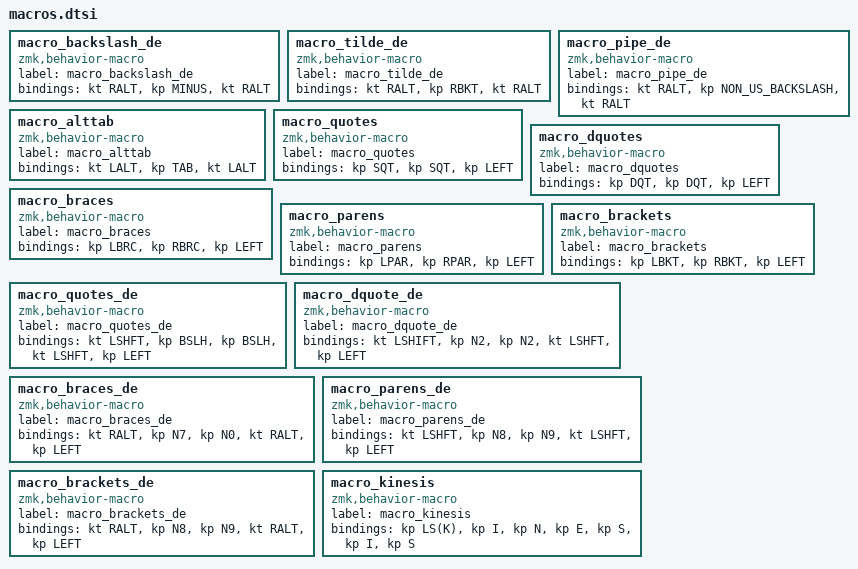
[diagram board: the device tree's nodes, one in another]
macro_backslash_de: macro_backslash_de{
compatible = "zmk,behavior-macro";
label = "macro_backslash_de";
#binding-cells = <0>;
bindings = <&kt RALT>, <&kp MINUS>, <&kt RALT>;
};
macro_tilde_de: macro_tilde_de{
compatible = "zmk,behavior-macro";
label = "macro_tilde_de";
#binding-cells = <0>;
bindings = <&kt RALT>, <&kp RBKT>, <&kt RALT>;
};
macro_pipe_de: macro_pipe_de{
compatible = "zmk,behavior-macro";
label = "macro_pipe_de";
#binding-cells = <0>;
bindings = <&kt RALT>, <&kp NON_US_BACKSLASH>, <&kt RALT>;
};
macro_alttab: macro_alttab{
compatible = "zmk,behavior-macro";
label = "macro_alttab";
#binding-cells = <0>;
bindings = <&kt LALT>, <&kp TAB>, <&kt LALT>;
};
macro_quotes: macro_quotes{
compatible = "zmk,behavior-macro";
label = "macro_quotes";
#binding-cells = <0>;
bindings = <&kp SQT>, <&kp SQT>, <&kp LEFT>;
};
macro_dquotes: macro_dquotes{
compatible = "zmk,behavior-macro";
label = "macro_dquotes";
#binding-cells = <0>;
bindings = <&kp DQT>, <&kp DQT>, <&kp LEFT>;
};
macro_braces: macro_braces{
compatible = "zmk,behavior-macro";
label = "macro_braces";
#binding-cells = <0>;
bindings = <&kp LBRC>, <&kp RBRC>, <&kp LEFT>;
};
macro_parens: macro_parens{
compatible = "zmk,behavior-macro";
label = "macro_parens";
#binding-cells = <0>;
bindings = <&kp LPAR>, <&kp RPAR>, <&kp LEFT>;
};
macro_brackets: macro_brackets{
compatible = "zmk,behavior-macro";
label = "macro_brackets";
#binding-cells = <0>;
bindings = <&kp LBKT>, <&kp RBKT>, <&kp LEFT>;
};
macro_quotes_de: macro_quotes_de{
compatible = "zmk,behavior-macro";
label = "macro_quotes_de";
#binding-cells = <0>;
bindings = <&kt LSHFT>, <&kp BSLH>, <&kp BSLH>, <&kt LSHFT>, <&kp LEFT>;
};
macro_dquote_de: macro_dquote_de{
compatible = "zmk,behavior-macro";
label = "macro_dquote_de";
#binding-cells = <0>;
bindings = <&kt LSHIFT>, <&kp N2>, <&kp N2>, <&kt LSHFT>, <&kp LEFT>;
};
macro_braces_de: macro_braces_de{
compatible = "zmk,behavior-macro";
label = "macro_braces_de";
#binding-cells = <0>;
bindings = <&kt RALT>, <&kp N7>, <&kp N0>, <&kt RALT>, <&kp LEFT>;
};
macro_parens_de: macro_parens_de{
compatible = "zmk,behavior-macro";
label = "macro_parens_de";
#binding-cells = <0>;
bindings = <&kt LSHFT>, <&kp N8>, <&kp N9>, <&kt LSHFT>, <&kp LEFT>;
};
macro_brackets_de: macro_brackets_de{
compatible = "zmk,behavior-macro";
label = "macro_brackets_de";
#binding-cells = <0>;
bindings = <&kt RALT>, <&kp N8>, <&kp N9>, <&kt RALT>, <&kp LEFT>;
};
macro_kinesis: macro_kinesis{
compatible = "zmk,behavior-macro";
label = "macro_kinesis";
#binding-cells = <0>;
bindings = <&kp LS(K)>, <&kp I>, <&kp N>, <&kp E>, <&kp S>, <&kp I>, <&kp S>;
};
